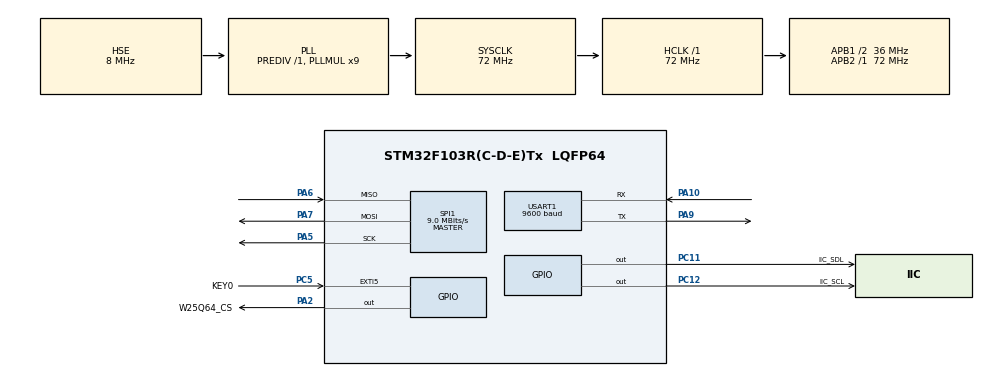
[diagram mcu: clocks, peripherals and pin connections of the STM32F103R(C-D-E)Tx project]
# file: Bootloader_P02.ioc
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Mcu.Family=STM32F1
Mcu.Name=STM32F103R(C-D-E)Tx
Mcu.Package=LQFP64
NVIC.EXTI9_5_IRQn=true\:0\:0\:false\:false\:true\:true\:true\:true
NVIC.PriorityGroup=NVIC_PRIORITYGROUP_2
NVIC.USART1_IRQn=true\:0\:0\:false\:false\:true\:true\:true\:true
PA10.Mode=Asynchronous
PA10.Signal=USART1_RX
PA13.Mode=Serial_Wire
PA13.Signal=SYS_JTMS-SWDIO
PA14.Mode=Serial_Wire
PA14.Signal=SYS_JTCK-SWCLK
PA2.GPIO_Label=W25Q64_CS
PA2.GPIO_Speed=GPIO_SPEED_FREQ_HIGH
PA2.PinState=GPIO_PIN_SET
PA2.Signal=GPIO_Output
PA5.Mode=Full_Duplex_Master
PA5.Signal=SPI1_SCK
PA6.Mode=Full_Duplex_Master
PA6.Signal=SPI1_MISO
PA7.Mode=Full_Duplex_Master
PA7.Signal=SPI1_MOSI
PA9.Mode=Asynchronous
PA9.Signal=USART1_TX
PC11.GPIO_Label=IIC_SDL
PC11.GPIO_ModeDefaultOutputPP=GPIO_MODE_OUTPUT_OD
PC11.GPIO_PuPd=GPIO_NOPULL
PC11.PinState=GPIO_PIN_SET
PC11.Signal=GPIO_Output
PC12.GPIO_Label=IIC_SCL
PC12.GPIO_ModeDefaultOutputPP=GPIO_MODE_OUTPUT_OD
PC12.GPIO_PuPd=GPIO_NOPULL
PC12.PinState=GPIO_PIN_SET
PC12.Signal=GPIO_Output
PC14-OSC32_IN.Mode=LSE-External-Oscillator
PC14-OSC32_IN.Signal=RCC_OSC32_IN
PC15-OSC32_OUT.Mode=LSE-External-Oscillator
PC15-OSC32_OUT.Signal=RCC_OSC32_OUT
PC5.GPIO_Label=KEY0
PC5.GPIO_ModeDefaultEXTI=GPIO_MODE_IT_FALLING
PC5.GPIO_PuPd=GPIO_PULLUP
PC5.Signal=GPXTI5
PD0-OSC_IN.Mode=HSE-External-Oscillator
PD0-OSC_IN.Signal=RCC_OSC_IN
PD1-OSC_OUT.Mode=HSE-External-Oscillator
PD1-OSC_OUT.Signal=RCC_OSC_OUT
ProjectManager.HeapSize=0x200
ProjectManager.StackSize=0x400
ProjectManager.TargetToolchain=MDK-ARM V5.32
RCC.AHBFreq_Value=72000000
RCC.APB1CLKDivider=RCC_HCLK_DIV2
RCC.APB1Freq_Value=36000000
RCC.APB1TimFreq_Value=72000000
RCC.APB2Freq_Value=72000000
RCC.APB2TimFreq_Value=72000000
RCC.HCLKFreq_Value=72000000
RCC.PLLMUL=RCC_PLL_MUL9
RCC.PLLSourceVirtual=RCC_PLLSOURCE_HSE
RCC.SYSCLKFreq_VALUE=72000000
RCC.SYSCLKSource=RCC_SYSCLKSOURCE_PLLCLK
RCC.USBFreq_Value=72000000
SPI1.BaudRatePrescaler=SPI_BAUDRATEPRESCALER_8
SPI1.CalculateBaudRate=9.0 MBits/s
SPI1.Direction=SPI_DIRECTION_2LINES
SPI1.Mode=SPI_MODE_MASTER
SPI1.VirtualType=VM_MASTER
USART1.BaudRate=9600
USART1.VirtualMode=VM_ASYNC
board=custom

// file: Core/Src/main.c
/* USER CODE BEGIN Header */
/**
  ******************************************************************************
  * @file           : main.c
  * @brief          : Main program body
  ******************************************************************************
  * @attention
  *
  * Copyright (c) 2026 STMicroelectronics.
  * All rights reserved.
  *
  * This software is licensed under terms that can be found in the LICENSE file
  * in the root directory of this software component.
  * If no LICENSE file comes with this software, it is provided AS-IS.
  *
  ******************************************************************************
  */
/* USER CODE END Header */
#include "main.h"
#include "spi.h"
#include "usart.h"
#include "gpio.h"

/* USER CODE BEGIN Includes */
#include "string.h"
//#include "int_bootloader.h"
//#include "App_bootloader.h"
#include "Int_w25q64.h"
#include "Int_w24c02.h"
#include "my_iic.h"
#include "APP_bootloader.h"
/* USER CODE END Includes */

void SystemClock_Config(void);
/* USER CODE BEGIN PFP */
extern uint16_t uart_rec_full_len; //接收数据的总长度
/* USER CODE END PFP */

/* USER CODE BEGIN 0 */
//#define REC_BUFF_LEN 512
/* USER CODE END 0 */

int main(void)
{

  /* MCU Configuration--------------------------------------------------------*/

  /* Reset of all peripherals, Initializes the Flash interface and the Systick. */
  HAL_Init();

  /* Configure the system clock */
  SystemClock_Config();

  /* Initialize all configured peripherals */
  MX_GPIO_Init();
  MX_USART1_UART_Init();
  MX_SPI1_Init();
  /* USER CODE BEGIN 2 */

   //1.初始化Bootloader
  App_Bootloader_Check_Update();

  //2.是否进入默认程序，恢复出厂设置
  App_bootloader_check_default();

  //3.根据状态进行更新
  App_bootloader_Update();

  //4.跳转到应用程序
  App_bootloader_Jump_App();

  /* USER CODE END 2 */

  /* Infinite loop */
  while (1)
  {

  }
}

void SystemClock_Config(void)
{
  RCC_OscInitTypeDef RCC_OscInitStruct = {0};
  RCC_ClkInitTypeDef RCC_ClkInitStruct = {0};

  /** Initializes the RCC Oscillators according to the specified parameters
  * in the RCC_OscInitTypeDef structure.
  */
  RCC_OscInitStruct.OscillatorType = RCC_OSCILLATORTYPE_HSE;
  RCC_OscInitStruct.HSEState = RCC_HSE_ON;
  RCC_OscInitStruct.HSEPredivValue = RCC_HSE_PREDIV_DIV1;
  RCC_OscInitStruct.HSIState = RCC_HSI_ON;
  RCC_OscInitStruct.PLL.PLLState = RCC_PLL_ON;
  RCC_OscInitStruct.PLL.PLLSource = RCC_PLLSOURCE_HSE;
  RCC_OscInitStruct.PLL.PLLMUL = RCC_PLL_MUL9;
  if (HAL_RCC_OscConfig(&RCC_OscInitStruct) != HAL_OK)
  {
    Error_Handler();
  }

  /** Initializes the CPU, AHB and APB buses clocks
  */
  RCC_ClkInitStruct.ClockType = RCC_CLOCKTYPE_HCLK|RCC_CLOCKTYPE_SYSCLK
                              |RCC_CLOCKTYPE_PCLK1|RCC_CLOCKTYPE_PCLK2;
  RCC_ClkInitStruct.SYSCLKSource = RCC_SYSCLKSOURCE_PLLCLK;
  RCC_ClkInitStruct.AHBCLKDivider = RCC_SYSCLK_DIV1;
  RCC_ClkInitStruct.APB1CLKDivider = RCC_HCLK_DIV2;
  RCC_ClkInitStruct.APB2CLKDivider = RCC_HCLK_DIV1;

  if (HAL_RCC_ClockConfig(&RCC_ClkInitStruct, FLASH_LATENCY_2) != HAL_OK)
  {
    Error_Handler();
  }
}

void Error_Handler(void)
{
  __disable_irq();
  while (1)
  {
  }
}
